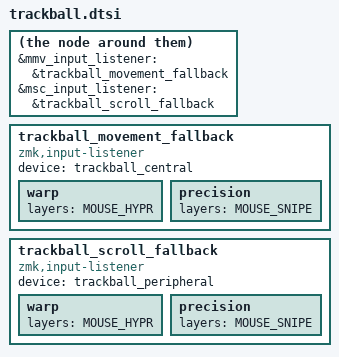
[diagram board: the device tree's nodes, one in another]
/* Fallback trackball configuration for crosses keyboard */

#include "trackball_base.dtsi"

/* Create input listeners for trackball devices from overlays */
 trackball_movement_fallback: trackball_movement_fallback {
  compatible = "zmk,input-listener";
  status = "okay";
  device = <&trackball_central>;  /* Reference device from right overlay */
  warp {
    layers = <MOUSE_HYPR>;
    /* input-processors = <&zip_xy_scaler 3 1>; */
  };
  precision {
    layers = <MOUSE_SNIPE>;
    /* input-processors = <&zip_xy_scaler 1 2>; */
  };
};

trackball_scroll_fallback: trackball_scroll_fallback {
  compatible = "zmk,input-listener";
  status = "okay";
  device = <&trackball_peripheral>;  /* Reference device from left overlay */
  warp {
    layers = <MOUSE_HYPR>;
    /* input-processors = <&zip_scroll_scaler 2 1>; */
  };
  precision {
    layers = <MOUSE_SNIPE>;
    /* input-processors = <&zip_scroll_scaler 1 2>; */
  };
};

/* Dual aliases - both available for fallback */
&mmv_input_listener = &trackball_movement_fallback;
&msc_input_listener = &trackball_scroll_fallback;
